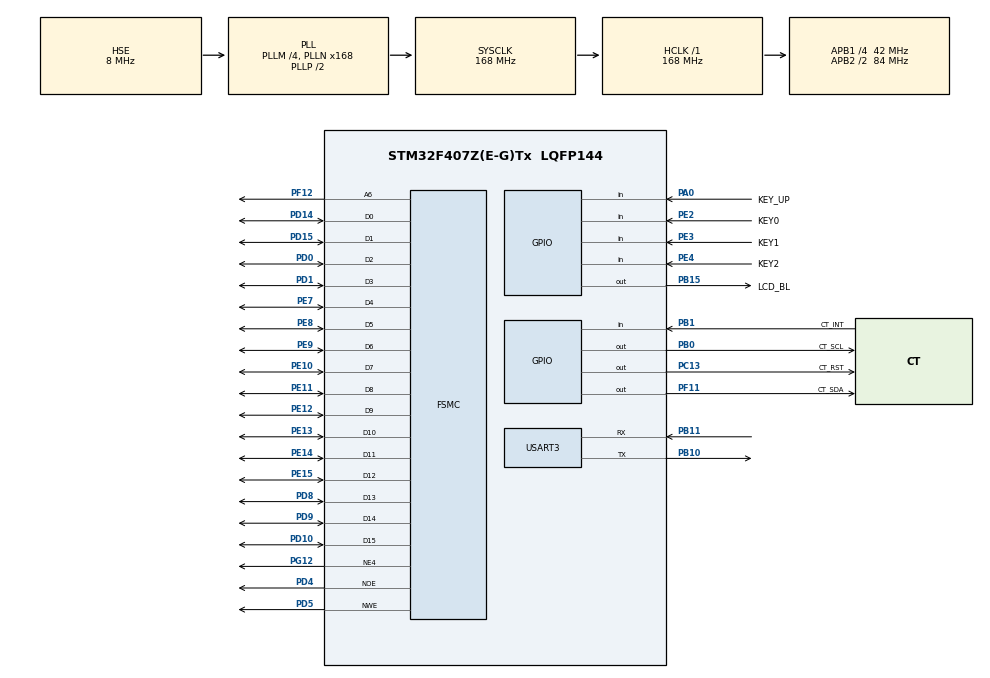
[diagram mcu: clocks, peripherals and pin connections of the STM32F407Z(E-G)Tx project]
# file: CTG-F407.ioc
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Dma.Request0=USART3_RX
Dma.Request1=USART3_TX
Dma.USART3_RX.0.Direction=DMA_PERIPH_TO_MEMORY
Dma.USART3_RX.0.FIFOMode=DMA_FIFOMODE_DISABLE
Dma.USART3_RX.0.Instance=DMA1_Stream1
Dma.USART3_RX.0.MemDataAlignment=DMA_MDATAALIGN_BYTE
Dma.USART3_RX.0.MemInc=DMA_MINC_ENABLE
Dma.USART3_RX.0.Mode=DMA_CIRCULAR
Dma.USART3_RX.0.PeriphDataAlignment=DMA_PDATAALIGN_BYTE
Dma.USART3_RX.0.PeriphInc=DMA_PINC_DISABLE
Dma.USART3_RX.0.Priority=DMA_PRIORITY_HIGH
Dma.USART3_TX.1.Direction=DMA_MEMORY_TO_PERIPH
Dma.USART3_TX.1.FIFOMode=DMA_FIFOMODE_DISABLE
Dma.USART3_TX.1.Instance=DMA1_Stream3
Dma.USART3_TX.1.MemDataAlignment=DMA_MDATAALIGN_BYTE
Dma.USART3_TX.1.MemInc=DMA_MINC_ENABLE
Dma.USART3_TX.1.Mode=DMA_NORMAL
Dma.USART3_TX.1.PeriphDataAlignment=DMA_PDATAALIGN_BYTE
Dma.USART3_TX.1.PeriphInc=DMA_PINC_DISABLE
Dma.USART3_TX.1.Priority=DMA_PRIORITY_LOW
FREERTOS.INCLUDE_xTaskGetHandle=1
FREERTOS.Tasks01=defaultTask,24,128,StartDefaultTask,Default,NULL,Dynamic,NULL,NULL
FREERTOS.configCHECK_FOR_STACK_OVERFLOW=1
FREERTOS.configTOTAL_HEAP_SIZE=40960
FSMC.AddressSetupTime1=15
FSMC.BusTurnAroundDuration1=0
FSMC.DataSetupTime1=60
FSMC.ExtendedAddressSetupTime1=2
FSMC.ExtendedBusTurnAroundDuration1=0
FSMC.ExtendedDataSetupTime1=4
FSMC.ExtendedMode1=FSMC_EXTENDED_MODE_ENABLE
Mcu.Family=STM32F4
Mcu.Name=STM32F407Z(E-G)Tx
Mcu.Package=LQFP144
NVIC.DMA1_Stream1_IRQn=true\:5\:0\:false\:false\:true\:true\:false\:true\:true
NVIC.DMA1_Stream3_IRQn=true\:5\:0\:false\:false\:true\:true\:false\:true\:true
NVIC.PriorityGroup=NVIC_PRIORITYGROUP_4
NVIC.TIM6_DAC_IRQn=true\:15\:0\:false\:false\:true\:false\:false\:true\:true
NVIC.TimeBase=TIM6_DAC_IRQn
NVIC.TimeBaseIP=TIM6
NVIC.USART3_IRQn=true\:5\:0\:false\:false\:true\:true\:true\:true\:true
PA0-WKUP.GPIO_Label=KEY_UP
PA0-WKUP.GPIO_PuPd=GPIO_PULLDOWN
PA0-WKUP.Signal=GPIO_Input
PA13.Mode=Serial_Wire
PA13.Signal=SYS_JTMS-SWDIO
PA14.Mode=Serial_Wire
PA14.Signal=SYS_JTCK-SWCLK
PB0.GPIO_Label=CT_SCL
PB0.GPIO_Speed=GPIO_SPEED_FREQ_HIGH
PB0.PinState=GPIO_PIN_SET
PB0.Signal=GPIO_Output
PB1.GPIO_Label=CT_INT
PB1.GPIO_PuPd=GPIO_PULLUP
PB1.Signal=GPIO_Input
PB10.Mode=Asynchronous
PB10.Signal=USART3_TX
PB11.GPIO_PuPd=GPIO_PULLUP
PB11.Mode=Asynchronous
PB11.Signal=USART3_RX
PB15.GPIO_Label=LCD_BL
PB15.GPIO_PuPd=GPIO_NOPULL
PB15.GPIO_Speed=GPIO_SPEED_FREQ_HIGH
PB15.PinState=GPIO_PIN_SET
PB15.Signal=GPIO_Output
PC13-ANTI_TAMP.GPIO_Label=CT_RST
PC13-ANTI_TAMP.PinState=GPIO_PIN_SET
PC13-ANTI_TAMP.Signal=GPIO_Output
PD0.Signal=FSMC_D2_DA2
PD1.Signal=FSMC_D3_DA3
PD10.Signal=FSMC_D15_DA15
PD14.Signal=FSMC_D0_DA0
PD15.Signal=FSMC_D1_DA1
PD4.Signal=FSMC_NOE
PD5.Signal=FSMC_NWE
PD8.Signal=FSMC_D13_DA13
PD9.Signal=FSMC_D14_DA14
PE10.Signal=FSMC_D7_DA7
PE11.Signal=FSMC_D8_DA8
PE12.Signal=FSMC_D9_DA9
PE13.Signal=FSMC_D10_DA10
PE14.Signal=FSMC_D11_DA11
PE15.Signal=FSMC_D12_DA12
PE2.GPIO_Label=KEY0
PE2.GPIO_PuPd=GPIO_PULLUP
PE2.Signal=GPIO_Input
PE3.GPIO_Label=KEY1
PE3.GPIO_PuPd=GPIO_PULLUP
PE3.Signal=GPIO_Input
PE4.GPIO_Label=KEY2
PE4.GPIO_PuPd=GPIO_PULLUP
PE4.Signal=GPIO_Input
PE7.Signal=FSMC_D4_DA4
PE8.Signal=FSMC_D5_DA5
PE9.Signal=FSMC_D6_DA6
PF11.GPIO_Label=CT_SDA
PF11.GPIO_ModeDefaultOutputPP=GPIO_MODE_OUTPUT_OD
PF11.GPIO_PuPd=GPIO_PULLUP
PF11.GPIO_Speed=GPIO_SPEED_FREQ_HIGH
PF11.PinState=GPIO_PIN_SET
PF11.Signal=GPIO_Output
PF12.Signal=FSMC_A6
PG12.Mode=NorPsramChipSelect4_1
PG12.Signal=FSMC_NE4
PH0-OSC_IN.Mode=HSE-External-Oscillator
PH0-OSC_IN.Signal=RCC_OSC_IN
PH1-OSC_OUT.Mode=HSE-External-Oscillator
PH1-OSC_OUT.Signal=RCC_OSC_OUT
ProjectManager.HeapSize=0x200
ProjectManager.StackSize=0x400
ProjectManager.TargetToolchain=MDK-ARM V5.32
RCC.48MHZClocksFreq_Value=84000000
RCC.AHBFreq_Value=168000000
RCC.APB1CLKDivider=RCC_HCLK_DIV4
RCC.APB1Freq_Value=42000000
RCC.APB1TimFreq_Value=84000000
RCC.APB2CLKDivider=RCC_HCLK_DIV2
RCC.APB2Freq_Value=84000000
RCC.APB2TimFreq_Value=168000000
RCC.CortexFreq_Value=168000000
RCC.HCLKFreq_Value=168000000
RCC.HSE_VALUE=8000000
RCC.HSI_VALUE=16000000
RCC.LSE_VALUE=32768
RCC.PLLM=4
RCC.PLLN=168
RCC.PLLSourceVirtual=RCC_PLLSOURCE_HSE
RCC.SYSCLKFreq_VALUE=168000000
RCC.SYSCLKSource=RCC_SYSCLKSOURCE_PLLCLK
RCC.VCOOutputFreq_Value=336000000
SH.FSMC_A6.0=FSMC_A6,A6_1
SH.FSMC_D0_DA0.0=FSMC_D0,16b-d1
SH.FSMC_D10_DA10.0=FSMC_D10,16b-d1
SH.FSMC_D11_DA11.0=FSMC_D11,16b-d1
SH.FSMC_D12_DA12.0=FSMC_D12,16b-d1
SH.FSMC_D13_DA13.0=FSMC_D13,16b-d1
SH.FSMC_D14_DA14.0=FSMC_D14,16b-d1
SH.FSMC_D15_DA15.0=FSMC_D15,16b-d1
SH.FSMC_D1_DA1.0=FSMC_D1,16b-d1
SH.FSMC_D2_DA2.0=FSMC_D2,16b-d1
SH.FSMC_D3_DA3.0=FSMC_D3,16b-d1
SH.FSMC_D4_DA4.0=FSMC_D4,16b-d1
SH.FSMC_D5_DA5.0=FSMC_D5,16b-d1
SH.FSMC_D6_DA6.0=FSMC_D6,16b-d1
SH.FSMC_D7_DA7.0=FSMC_D7,16b-d1
SH.FSMC_D8_DA8.0=FSMC_D8,16b-d1
SH.FSMC_D9_DA9.0=FSMC_D9,16b-d1
SH.FSMC_NOE.0=FSMC_NOE,Lcd1
SH.FSMC_NWE.0=FSMC_NWE,Lcd1
TIM2.Prescaler=83
USART3.VirtualMode=VM_ASYNC
VP_FREERTOS_VS_CMSIS_V2.Mode=CMSIS_V2
VP_SYS_VS_tim6.Mode=TIM6
VP_TIM2_VS_ClockSourceINT.Mode=Internal
board=custom

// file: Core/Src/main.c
/* USER CODE BEGIN Header */
/**
  ******************************************************************************
  * @file           : main.c
  * @brief          : Main program body
  ******************************************************************************
  * @attention
  *
  * Copyright (c) 2026 STMicroelectronics.
  * All rights reserved.
  *
  * This software is licensed under terms that can be found in the LICENSE file
  * in the root directory of this software component.
  * If no LICENSE file comes with this software, it is provided AS-IS.
  *
  ******************************************************************************
  */
/* USER CODE END Header */
#include "main.h"
#include "cmsis_os.h"
#include "dma.h"
#include "tim.h"
#include "usart.h"
#include "gpio.h"
#include "fsmc.h"

/* USER CODE BEGIN Includes */
#include "bsp.h"
#include "app_main.h"
#include "tim.h"
#include "lvgl.h"
/* USER CODE END Includes */

void SystemClock_Config(void);
void MX_FREERTOS_Init(void);

int main(void)
{

  /* MCU Configuration--------------------------------------------------------*/

  /* Reset of all peripherals, Initializes the Flash interface and the Systick. */
  HAL_Init();

  /* Configure the system clock */
  SystemClock_Config();

  /* Initialize all configured peripherals */
  MX_GPIO_Init();
  MX_DMA_Init();
  MX_FSMC_Init();
  MX_TIM2_Init();
  MX_USART3_UART_Init();
  /* USER CODE BEGIN 2 */
  HAL_TIM_Base_Start(&htim2);
  bsp_init();
  /* USER CODE END 2 */

  /* Init scheduler */
  osKernelInitialize();  /* Call init function for freertos objects (in cmsis_os2.c) */
  MX_FREERTOS_Init();

  /* Start scheduler */
  osKernelStart();

  /* We should never get here as control is now taken by the scheduler */

  /* Infinite loop */
  while (1)
  {

  }
}

void SystemClock_Config(void)
{
  RCC_OscInitTypeDef RCC_OscInitStruct = {0};
  RCC_ClkInitTypeDef RCC_ClkInitStruct = {0};

  /** Configure the main internal regulator output voltage
  */
  __HAL_RCC_PWR_CLK_ENABLE();
  __HAL_PWR_VOLTAGESCALING_CONFIG(PWR_REGULATOR_VOLTAGE_SCALE1);

  /** Initializes the RCC Oscillators according to the specified parameters
  * in the RCC_OscInitTypeDef structure.
  */
  RCC_OscInitStruct.OscillatorType = RCC_OSCILLATORTYPE_HSE;
  RCC_OscInitStruct.HSEState = RCC_HSE_ON;
  RCC_OscInitStruct.PLL.PLLState = RCC_PLL_ON;
  RCC_OscInitStruct.PLL.PLLSource = RCC_PLLSOURCE_HSE;
  RCC_OscInitStruct.PLL.PLLM = 4;
  RCC_OscInitStruct.PLL.PLLN = 168;
  RCC_OscInitStruct.PLL.PLLP = RCC_PLLP_DIV2;
  RCC_OscInitStruct.PLL.PLLQ = 4;
  if (HAL_RCC_OscConfig(&RCC_OscInitStruct) != HAL_OK)
  {
    Error_Handler();
  }

  /** Initializes the CPU, AHB and APB buses clocks
  */
  RCC_ClkInitStruct.ClockType = RCC_CLOCKTYPE_HCLK|RCC_CLOCKTYPE_SYSCLK
                              |RCC_CLOCKTYPE_PCLK1|RCC_CLOCKTYPE_PCLK2;
  RCC_ClkInitStruct.SYSCLKSource = RCC_SYSCLKSOURCE_PLLCLK;
  RCC_ClkInitStruct.AHBCLKDivider = RCC_SYSCLK_DIV1;
  RCC_ClkInitStruct.APB1CLKDivider = RCC_HCLK_DIV4;
  RCC_ClkInitStruct.APB2CLKDivider = RCC_HCLK_DIV2;

  if (HAL_RCC_ClockConfig(&RCC_ClkInitStruct, FLASH_LATENCY_5) != HAL_OK)
  {
    Error_Handler();
  }
}

/* USER CODE BEGIN 4 */

void delay_us(uint32_t us)
{
  uint32_t t0 = TIM2->CNT;
  while ((TIM2->CNT - t0) < us);
}

/* USER CODE END 4 */

void HAL_TIM_PeriodElapsedCallback(TIM_HandleTypeDef *htim)
{
  if (htim->Instance == TIM6)
  {
	lv_tick_inc(1);
    HAL_IncTick();
  }
}

void Error_Handler(void)
{
  __disable_irq();
  while (1)
  {
  }
}

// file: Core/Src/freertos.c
/* USER CODE BEGIN Header */
/**
  ******************************************************************************
  * File Name          : freertos.c
  * Description        : Code for freertos applications
  ******************************************************************************
  * @attention
  *
  * Copyright (c) 2026 STMicroelectronics.
  * All rights reserved.
  *
  * This software is licensed under terms that can be found in the LICENSE file
  * in the root directory of this software component.
  * If no LICENSE file comes with this software, it is provided AS-IS.
  *
  ******************************************************************************
  */
/* USER CODE END Header */

#include "FreeRTOS.h"
#include "task.h"
#include "main.h"
#include "cmsis_os.h"

/* USER CODE BEGIN Includes */
#include "app_main.h"
/* USER CODE END Includes */

/* Definitions for defaultTask */
osThreadId_t defaultTaskHandle;
const osThreadAttr_t defaultTask_attributes = {
  .name = "defaultTask",
  .stack_size = 128 * 4,
  .priority = (osPriority_t) osPriorityNormal,
};

void StartDefaultTask(void *argument);

void MX_FREERTOS_Init(void); /* (MISRA C 2004 rule 8.1) */

/* Hook prototypes */
void vApplicationStackOverflowHook(xTaskHandle xTask, signed char *pcTaskName);

/* USER CODE BEGIN 4 */
void vApplicationStackOverflowHook(xTaskHandle xTask, signed char *pcTaskName)
{
   /* Run time stack overflow checking is performed if
   configCHECK_FOR_STACK_OVERFLOW is defined to 1 or 2. This hook function is
   called if a stack overflow is detected. */
}
/* USER CODE END 4 */

void MX_FREERTOS_Init(void) {

  /* Create the thread(s) */
  /* creation of defaultTask */
  defaultTaskHandle = osThreadNew(StartDefaultTask, NULL, &defaultTask_attributes);

}

void StartDefaultTask(void *argument)
{
  /* USER CODE BEGIN StartDefaultTask */
  App_TaskCreate();
  osThreadTerminate(defaultTaskHandle);
  /* Infinite loop */
  for(;;)
  {
    osDelay(1);
  }
  /* USER CODE END StartDefaultTask */
}
